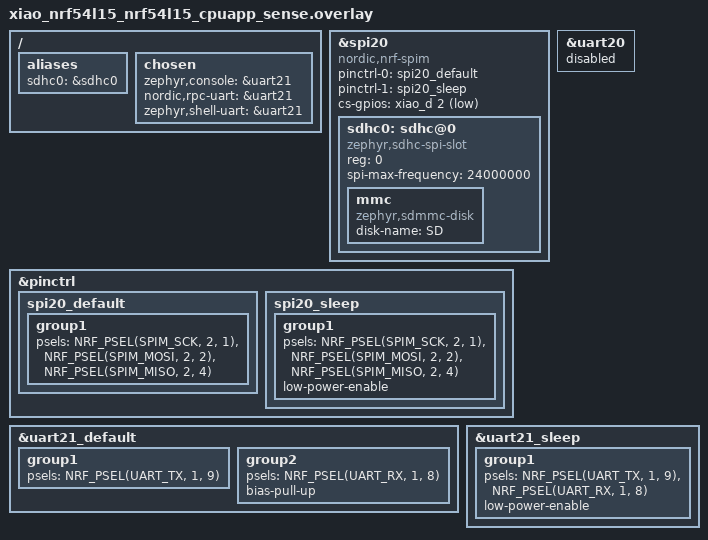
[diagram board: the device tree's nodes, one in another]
/*
 * SD Card configuration for XIAO nRF54L15 with Expansion Base.
 *
 * NOTE: The default `xiao_spi` (spi00) is a high-speed channel and cannot be used for SD cards,
 * which require a lower frequency for initialization. This overlay provides two alternative methods.
 *
 * --- METHOD 1: Use low-speed hardware SPI (spi20) --- [DEFAULT]
 * This method uses the `spi20` peripheral.
 * - Pro: Uses hardware SPI for better performance.
 * - Con: `spi20` conflicts with `uart20`. To maintain serial logging, `uart20` is disabled,
 *   and the console is redirected to `uart21` (xiao_serial), which is mapped to the USB serial pins.
 *
 * --- METHOD 2: Use Software SPI (bit-bang) ---
 * This method emulates SPI in software. The section for this is commented out below.
 * - Pro: Avoids hardware resource conflicts.
 * - Con: Lower performance than hardware SPI.
 *
 * --- How to Switch ---
 * To switch between methods, comment out the active section and uncomment the desired section.
 *
 * - To use Method 1 (Hardware SPI): Ensure the "METHOD 1" block is UNCOMMENTED and the "METHOD 2" block is COMMENTED.
 * - To use Method 2 (Software SPI): COMMENT OUT the "METHOD 1" block and UNCOMMENT the "METHOD 2" block.
 */


 /*
 * =============================================================================
 * METHOD 1: Use low-speed hardware SPI (spi20) [DEFAULT]
 * To use this, make sure this block is UNCOMMENTED and METHOD 2 is COMMENTED.
 * =============================================================================
 */
/ {
	aliases {
		sdhc0 = &sdhc0;
	};

	chosen {
		zephyr,console = &uart21;
		nordic,rpc-uart = &uart21;
		zephyr,shell-uart = &uart21;
	};
};

&spi20 {
	compatible = "nordic,nrf-spim";
	pinctrl-names = "default", "sleep";
	pinctrl-0 = <&spi20_default>;
	pinctrl-1 = <&spi20_sleep>;
	status = "okay";

	cs-gpios = <&xiao_d 2 (GPIO_ACTIVE_LOW | GPIO_PULL_UP)>;
	sdhc0: sdhc@0 {
		
			compatible = "zephyr,sdhc-spi-slot";
			reg = <0>;
			status = "okay";
			mmc {
				compatible = "zephyr,sdmmc-disk";
				disk-name = "SD";
				status = "okay";
			};
			spi-max-frequency = <24000000>;
		};
};

&uart20 {
	status = "disabled";
};

&pinctrl {
	spi20_default: spi20_default {
		group1 {
			psels = <NRF_PSEL(SPIM_SCK, 2, 1)>,
					<NRF_PSEL(SPIM_MOSI, 2, 2)>,
					<NRF_PSEL(SPIM_MISO, 2, 4)>;
		};
	};

	spi20_sleep: spi20_sleep {
		group1 {
			psels = <NRF_PSEL(SPIM_SCK, 2, 1)>,
					<NRF_PSEL(SPIM_MOSI, 2, 2)>,
					<NRF_PSEL(SPIM_MISO, 2, 4)>;
			low-power-enable;
		};
	};
};

&uart21_default {
	group1 {
		psels = <NRF_PSEL(UART_TX, 1, 9)>;
	};

	group2 {
		psels = <NRF_PSEL(UART_RX, 1, 8)>;
		bias-pull-up;
	};
};

&uart21_sleep {
	group1 {
		psels = <NRF_PSEL(UART_TX, 1, 9)>,
			<NRF_PSEL(UART_RX, 1, 8)>;
		low-power-enable;
	};
};

/*
 * =============================================================================
 * METHOD 2: Use Software SPI (bit-bang)
 * To use this, COMMENT OUT METHOD 1 above and UNCOMMENT the block below.
 * =============================================================================
 */
// / {
// 	spibb0: spibb0 {
// 		compatible = "zephyr,spi-bitbang";
// 		status = "okay";
// 		#address-cells = <1>;
// 		#size-cells = <0>;
// 		clk-gpios = <&gpio2 1 GPIO_ACTIVE_HIGH>;
// 		mosi-gpios = <&gpio2 2 GPIO_ACTIVE_HIGH>;
// 		miso-gpios = <&gpio2 4 GPIO_ACTIVE_HIGH>;
// 		cs-gpios = <&gpio1 6 GPIO_ACTIVE_LOW>;

// 		sdhc0: sdhc@0 {
// 			compatible = "zephyr,sdhc-spi-slot";
// 			reg = <0>;
// 			status = "okay";
// 			mmc {
// 				compatible = "zephyr,sdmmc-disk";
// 				disk-name = "SD";
// 				status = "okay";
// 			};
// 			spi-max-frequency = <24000000>;
// 		};
// 	};

// 	aliases {
// 		sdhc0 = &sdhc0;
// 	};
// };

// &xiao_spi {
// 	status = "disabled";
// };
